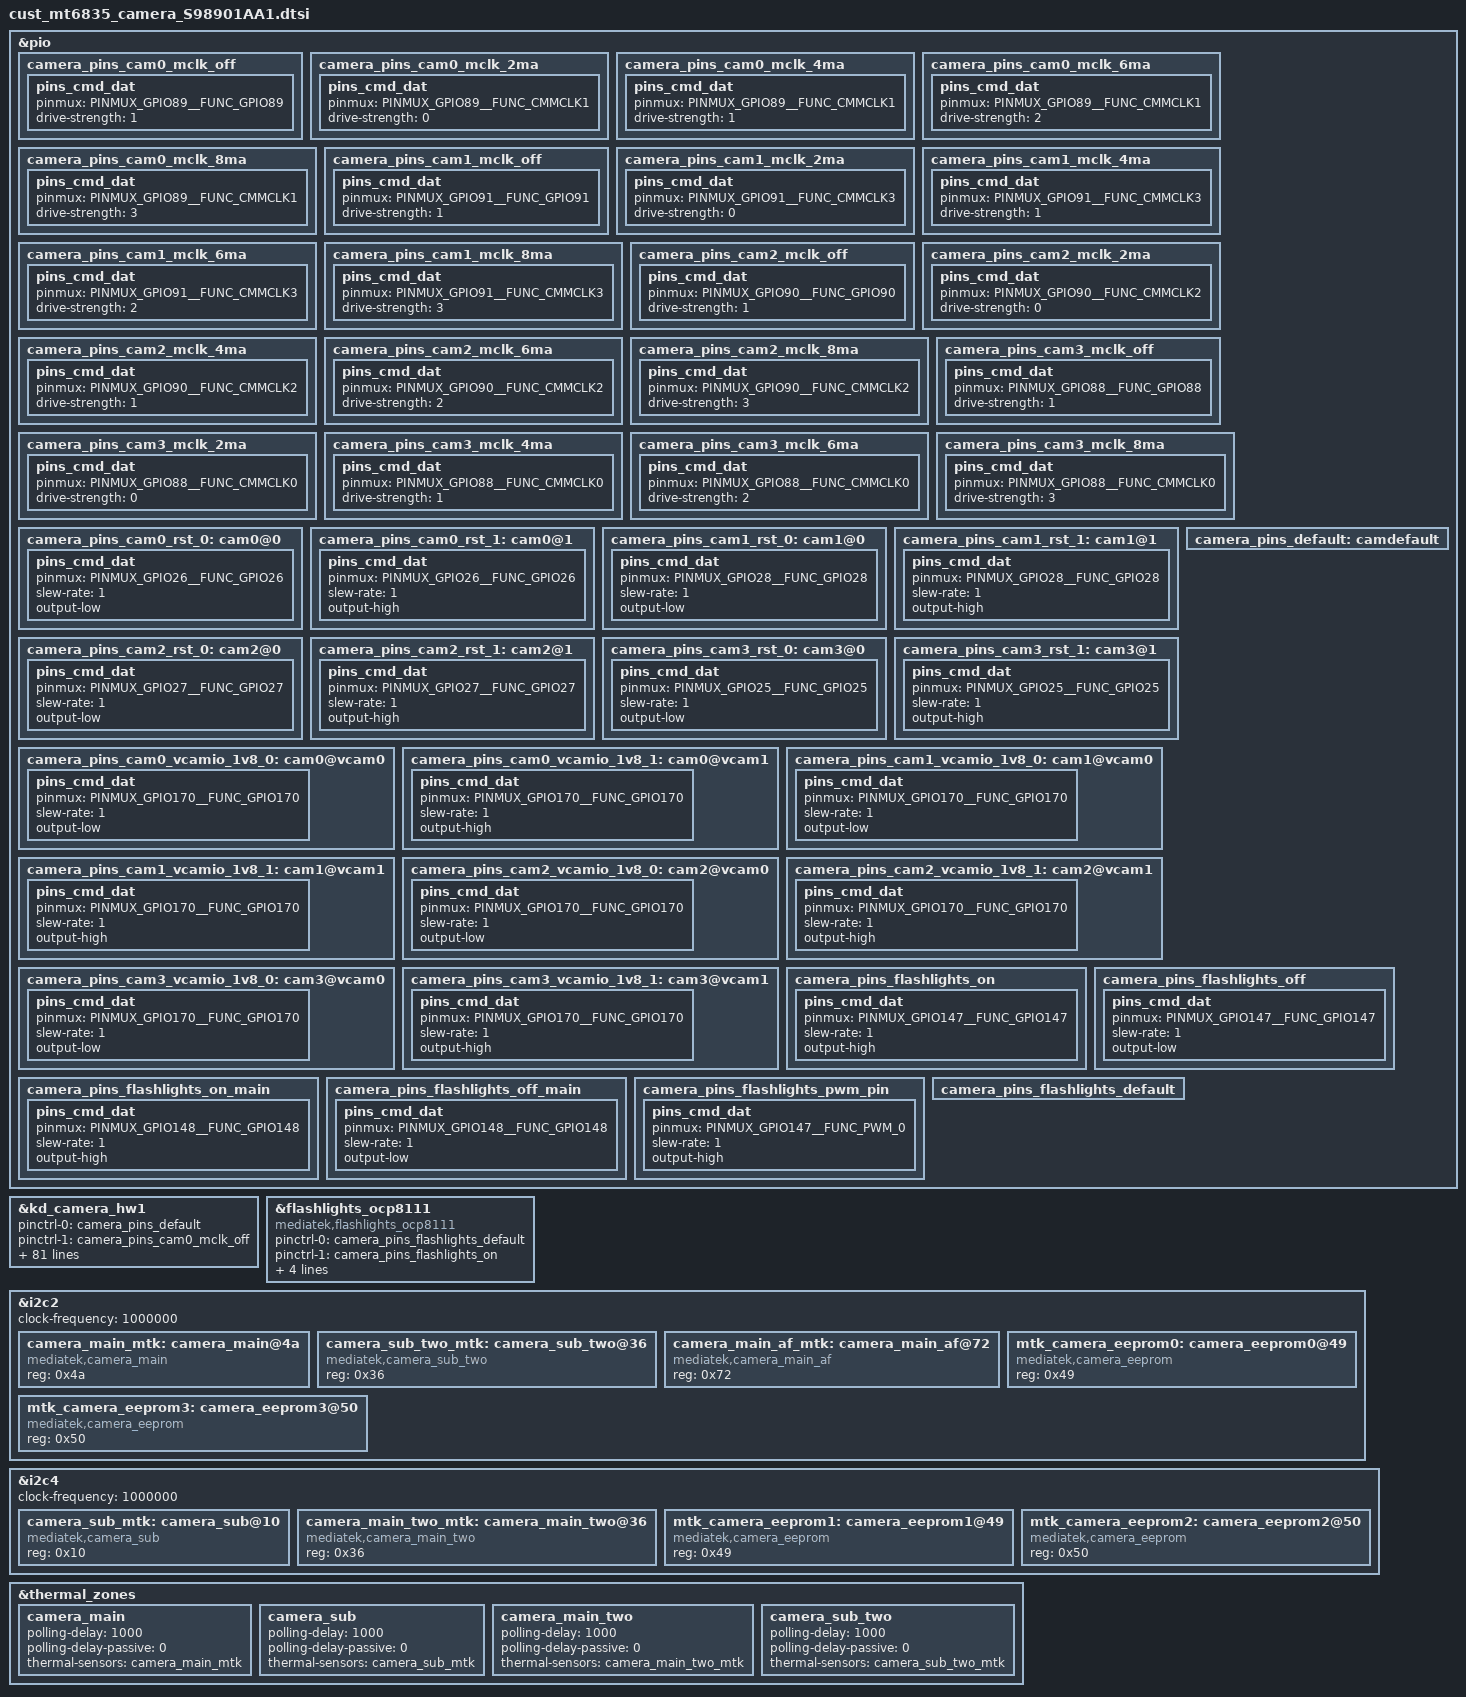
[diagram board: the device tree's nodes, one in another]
// SPDX-License-Identifier: GPL-2.0
/* Copyright (c) 2020 MediaTek Inc. */
#include "mediatek/et5904.dtsi"

/* CAMERA GPIO standardization */
&pio {
	camera_pins_cam0_mclk_off: camera_pins_cam0_mclk_off {
		pins_cmd_dat {
			pinmux = <PINMUX_GPIO89__FUNC_GPIO89>;
			drive-strength = <1>;
		};
	};
	camera_pins_cam0_mclk_2ma: camera_pins_cam0_mclk_2ma {
		pins_cmd_dat {
			pinmux = <PINMUX_GPIO89__FUNC_CMMCLK1>;
			drive-strength = <0>;
		};
	};
	camera_pins_cam0_mclk_4ma: camera_pins_cam0_mclk_4ma {
		pins_cmd_dat {
			pinmux = <PINMUX_GPIO89__FUNC_CMMCLK1>;
			drive-strength = <1>;
		};
	};
	camera_pins_cam0_mclk_6ma: camera_pins_cam0_mclk_6ma {
		pins_cmd_dat {
			pinmux = <PINMUX_GPIO89__FUNC_CMMCLK1>;
			drive-strength = <2>;
		};
	};
	camera_pins_cam0_mclk_8ma: camera_pins_cam0_mclk_8ma {
		pins_cmd_dat {
			pinmux = <PINMUX_GPIO89__FUNC_CMMCLK1>;
			drive-strength = <3>;
		};
	};

	camera_pins_cam1_mclk_off: camera_pins_cam1_mclk_off {
		pins_cmd_dat {
			pinmux = <PINMUX_GPIO91__FUNC_GPIO91>;
			drive-strength = <1>;
		};
	};
	camera_pins_cam1_mclk_2ma: camera_pins_cam1_mclk_2ma {
		pins_cmd_dat {
			pinmux = <PINMUX_GPIO91__FUNC_CMMCLK3>;
			drive-strength = <0>;
		};
	};
	camera_pins_cam1_mclk_4ma: camera_pins_cam1_mclk_4ma {
		pins_cmd_dat {
			pinmux = <PINMUX_GPIO91__FUNC_CMMCLK3>;
			drive-strength = <1>;
		};
	};
	camera_pins_cam1_mclk_6ma: camera_pins_cam1_mclk_6ma {
		pins_cmd_dat {
			pinmux = <PINMUX_GPIO91__FUNC_CMMCLK3>;
			drive-strength = <2>;
		};
	};
	camera_pins_cam1_mclk_8ma: camera_pins_cam1_mclk_8ma {
		pins_cmd_dat {
			pinmux = <PINMUX_GPIO91__FUNC_CMMCLK3>;
			drive-strength = <3>;
		};
	};
	camera_pins_cam2_mclk_off: camera_pins_cam2_mclk_off {
		pins_cmd_dat {
			pinmux = <PINMUX_GPIO90__FUNC_GPIO90>;
			drive-strength = <1>;
		};
	};
	camera_pins_cam2_mclk_2ma: camera_pins_cam2_mclk_2ma {
		pins_cmd_dat {
			pinmux = <PINMUX_GPIO90__FUNC_CMMCLK2>;
			drive-strength = <0>;
		};
	};
	camera_pins_cam2_mclk_4ma: camera_pins_cam2_mclk_4ma {
		pins_cmd_dat {
			pinmux = <PINMUX_GPIO90__FUNC_CMMCLK2>;
			drive-strength = <1>;
		};
	};
	camera_pins_cam2_mclk_6ma: camera_pins_cam2_mclk_6ma {
		pins_cmd_dat {
			pinmux = <PINMUX_GPIO90__FUNC_CMMCLK2>;
			drive-strength = <2>;
		};
	};
	camera_pins_cam2_mclk_8ma: camera_pins_cam2_mclk_8ma {
		pins_cmd_dat {
			pinmux = <PINMUX_GPIO90__FUNC_CMMCLK2>;
			drive-strength = <3>;
		};
	};

	camera_pins_cam3_mclk_off: camera_pins_cam3_mclk_off {
		pins_cmd_dat {
			pinmux = <PINMUX_GPIO88__FUNC_GPIO88>;
			drive-strength = <1>;
		};
	};
	camera_pins_cam3_mclk_2ma: camera_pins_cam3_mclk_2ma {
		pins_cmd_dat {
			pinmux = <PINMUX_GPIO88__FUNC_CMMCLK0>;
			drive-strength = <0>;
		};
	};
	camera_pins_cam3_mclk_4ma: camera_pins_cam3_mclk_4ma {
		pins_cmd_dat {
			pinmux = <PINMUX_GPIO88__FUNC_CMMCLK0>;
			drive-strength = <1>;
		};
	};
	camera_pins_cam3_mclk_6ma: camera_pins_cam3_mclk_6ma {
		pins_cmd_dat {
			pinmux = <PINMUX_GPIO88__FUNC_CMMCLK0>;
			drive-strength = <2>;
		};
	};
	camera_pins_cam3_mclk_8ma: camera_pins_cam3_mclk_8ma {
		pins_cmd_dat {
			pinmux = <PINMUX_GPIO88__FUNC_CMMCLK0>;
			drive-strength = <3>;
		};
	};


	camera_pins_cam0_rst_0: cam0@0 {
		pins_cmd_dat {
			pinmux = <PINMUX_GPIO26__FUNC_GPIO26>;
			slew-rate = <1>;
			output-low;
		};
	};
	camera_pins_cam0_rst_1: cam0@1 {
		pins_cmd_dat {
			pinmux = <PINMUX_GPIO26__FUNC_GPIO26>;
			slew-rate = <1>;
			output-high;
		};
	};

	camera_pins_cam1_rst_0: cam1@0 {
		pins_cmd_dat {
			pinmux = <PINMUX_GPIO28__FUNC_GPIO28>;
			slew-rate = <1>;
			output-low;
		};
	};
	camera_pins_cam1_rst_1: cam1@1 {
		pins_cmd_dat {
			pinmux = <PINMUX_GPIO28__FUNC_GPIO28>;
			slew-rate = <1>;
			output-high;
		};
	};
	camera_pins_cam2_rst_0: cam2@0 {
		pins_cmd_dat {
			pinmux = <PINMUX_GPIO27__FUNC_GPIO27>;
			slew-rate = <1>;
			output-low;
		};
	};
	camera_pins_cam2_rst_1: cam2@1 {
		pins_cmd_dat {
			pinmux = <PINMUX_GPIO27__FUNC_GPIO27>;
			slew-rate = <1>;
			output-high;
		};
	};
		camera_pins_cam3_rst_0: cam3@0 {
		pins_cmd_dat {
			pinmux = <PINMUX_GPIO25__FUNC_GPIO25>;
			slew-rate = <1>;
			output-low;
		};
	};
	camera_pins_cam3_rst_1: cam3@1 {
		pins_cmd_dat {
			pinmux = <PINMUX_GPIO25__FUNC_GPIO25>;
			slew-rate = <1>;
			output-high;
		};
	};

	camera_pins_cam0_vcamio_1v8_0: cam0@vcam0 {
		pins_cmd_dat {
			pinmux = <PINMUX_GPIO170__FUNC_GPIO170>;
			slew-rate = <1>;
			output-low;
		};
	};
	camera_pins_cam0_vcamio_1v8_1: cam0@vcam1 {
		pins_cmd_dat {
			pinmux = <PINMUX_GPIO170__FUNC_GPIO170>;
			slew-rate = <1>;
			output-high;
		};
	};
	camera_pins_cam1_vcamio_1v8_0: cam1@vcam0 {
		pins_cmd_dat {
			pinmux = <PINMUX_GPIO170__FUNC_GPIO170>;
			slew-rate = <1>;
			output-low;
		};
	};
	camera_pins_cam1_vcamio_1v8_1: cam1@vcam1 {
		pins_cmd_dat {
			pinmux = <PINMUX_GPIO170__FUNC_GPIO170>;
			slew-rate = <1>;
			output-high;
		};
	};
	camera_pins_cam2_vcamio_1v8_0: cam2@vcam0 {
		pins_cmd_dat {
			pinmux = <PINMUX_GPIO170__FUNC_GPIO170>;
			slew-rate = <1>;
			output-low;
		};
	};
	camera_pins_cam2_vcamio_1v8_1: cam2@vcam1 {
		pins_cmd_dat {
			pinmux = <PINMUX_GPIO170__FUNC_GPIO170>;
			slew-rate = <1>;
			output-high;
		};
	};
	camera_pins_cam3_vcamio_1v8_0: cam3@vcam0 {
		pins_cmd_dat {
			pinmux = <PINMUX_GPIO170__FUNC_GPIO170>;
			slew-rate = <1>;
			output-low;
		};
	};
	camera_pins_cam3_vcamio_1v8_1: cam3@vcam1 {
		pins_cmd_dat {
			pinmux = <PINMUX_GPIO170__FUNC_GPIO170>;
			slew-rate = <1>;
			output-high;
		};
	};

	camera_pins_default: camdefault {
	};
};

&kd_camera_hw1 {
	pinctrl-names = "default",
			"cam0_mclk_off",
			"cam0_mclk_2mA", "cam0_mclk_4mA",
			"cam0_mclk_6mA", "cam0_mclk_8mA",
			"cam1_mclk_off",
			"cam1_mclk_2mA", "cam1_mclk_4mA",
			"cam1_mclk_6mA", "cam1_mclk_8mA",
			"cam2_mclk_off",
			"cam2_mclk_2mA", "cam2_mclk_4mA",
			"cam2_mclk_6mA", "cam2_mclk_8mA",
			"cam3_mclk_off",
			"cam3_mclk_2mA", "cam3_mclk_4mA",
			"cam3_mclk_6mA", "cam3_mclk_8mA",
			"cam0_rst0", "cam0_rst1",
			"cam1_rst0", "cam1_rst1",
			"cam2_rst0", "cam2_rst1",
			"cam3_rst0", "cam3_rst1",
			"cam0_ldo_vcamio_0", "cam0_ldo_vcamio_1",
			"cam1_ldo_vcamio_0", "cam1_ldo_vcamio_1",
			"cam2_ldo_vcamio_0", "cam2_ldo_vcamio_1",
			"cam3_ldo_vcamio_0", "cam3_ldo_vcamio_1";

    pinctrl-0 = <&camera_pins_default>;
	pinctrl-1 = <&camera_pins_cam0_mclk_off>;
	pinctrl-2 = <&camera_pins_cam0_mclk_2ma>;
	pinctrl-3 = <&camera_pins_cam0_mclk_4ma>;
	pinctrl-4 = <&camera_pins_cam0_mclk_6ma>;
	pinctrl-5 = <&camera_pins_cam0_mclk_8ma>;
	pinctrl-6 = <&camera_pins_cam1_mclk_off>;
	pinctrl-7 = <&camera_pins_cam1_mclk_2ma>;
	pinctrl-8 = <&camera_pins_cam1_mclk_4ma>;
	pinctrl-9 = <&camera_pins_cam1_mclk_6ma>;
	pinctrl-10 = <&camera_pins_cam1_mclk_8ma>;
	pinctrl-11 = <&camera_pins_cam2_mclk_off>;
	pinctrl-12 = <&camera_pins_cam2_mclk_2ma>;
	pinctrl-13 = <&camera_pins_cam2_mclk_4ma>;
	pinctrl-14 = <&camera_pins_cam2_mclk_6ma>;
	pinctrl-15 = <&camera_pins_cam2_mclk_8ma>;
	pinctrl-16 = <&camera_pins_cam3_mclk_off>;
	pinctrl-17 = <&camera_pins_cam3_mclk_2ma>;
	pinctrl-18 = <&camera_pins_cam3_mclk_4ma>;
	pinctrl-19 = <&camera_pins_cam3_mclk_6ma>;
	pinctrl-20 = <&camera_pins_cam3_mclk_8ma>;
	pinctrl-21 = <&camera_pins_cam0_rst_0>;
	pinctrl-22 = <&camera_pins_cam0_rst_1>;
	pinctrl-23 = <&camera_pins_cam1_rst_0>;
	pinctrl-24 = <&camera_pins_cam1_rst_1>;
	pinctrl-25 = <&camera_pins_cam2_rst_0>;
	pinctrl-26 = <&camera_pins_cam2_rst_1>;
	pinctrl-27 = <&camera_pins_cam3_rst_0>;
	pinctrl-28 = <&camera_pins_cam3_rst_1>;
	pinctrl-29 = <&camera_pins_cam0_vcamio_1v8_0>;
	pinctrl-30 = <&camera_pins_cam0_vcamio_1v8_1>;
	pinctrl-31 = <&camera_pins_cam1_vcamio_1v8_0>;
	pinctrl-32 = <&camera_pins_cam1_vcamio_1v8_1>;
	pinctrl-33 = <&camera_pins_cam2_vcamio_1v8_0>;
	pinctrl-34 = <&camera_pins_cam2_vcamio_1v8_1>;
	pinctrl-35 = <&camera_pins_cam3_vcamio_1v8_0>;
	pinctrl-36 = <&camera_pins_cam3_vcamio_1v8_1>;

	cam0_vcama-supply = <&et04_ldo3>;
	cam1_vcama-supply = <&et04_ldo3>;
	cam2_vcama-supply = <&et04_ldo3>;
	cam3_vcama-supply = <&et04_ldo3>;
	cam0_vcamd-supply = <&et04_ldo2>;
	cam1_vcamd-supply = <&et04_ldo2>;
	cam2_vcamd-supply = <&et04_ldo1>;
	cam0_vcamaf-supply = <&et04_ldo4>;

	cam0_vcama1-supply = <&et04_ldo1>; //wide DVDD
	cam1_vcama1-supply = <&et04_ldo1>; //wide DVDD
	cam2_vcama1-supply = <&et04_ldo2>; //front main/front DVDD
	cam3_vcama1-supply = <&et04_ldo2>; //front main/front DVDD
	cam3_vcamd-supply  = <&et04_ldo1>; //wide DVDD

	cam0_enable_sensor = "w3s5kjn1reartxd_mipi_raw w3hi5022qrearjk_mipi_raw w3gc50e0reartxd_mipi_raw";
	cam1_enable_sensor = "w3ov13b10frontdc_mipi_raw w3gc13a0frontlh_mipi_raw w3sc1321csfrontlce_mipi_raw w3sc1300csfronttxd_mipi_raw";
	cam2_enable_sensor = "w3gc5035widesj_mipi_raw w3sc520cswidelce_mipi_raw";
	cam3_enable_sensor = "w3sc201acsmicrocxt_mipi_raw w3gc02m3microlh_mipi_raw w3c2599microsj_mipi_raw";

	cam0_pin_mclk = "mclk";
	cam0_pin_rst = "gpio";
	cam0_pin_vcama = "regulator";
	cam0_pin_vcamio = "gpio";
	cam0_pin_vcamd = "regulator";
	cam0_pin_vcamaf = "regulator";
	cam1_pin_mclk = "mclk";
	cam1_pin_rst = "gpio";
	cam1_pin_vcama = "regulator";
	cam1_pin_vcamio = "gpio";
	cam1_pin_vcamd = "regulator";
	cam2_pin_mclk = "mclk";
	cam2_pin_rst = "gpio";
	cam2_pin_vcama = "regulator";
	cam2_pin_vcamio = "gpio";
	cam2_pin_vcamd = "regulator";
	cam3_pin_mclk = "mclk";
	cam3_pin_rst = "gpio";
	cam3_pin_vcama = "regulator";
	cam3_pin_vcamio = "gpio";

	cam0_pin_vcama1 = "regulator";
	cam1_pin_vcama1 = "regulator";
	cam2_pin_vcama1 = "regulator";
	cam3_pin_vcama1 = "regulator";
	cam3_pin_vcamd  = "regulator";

	status = "okay";
};


&pio {
	camera_pins_flashlights_on: camera_pins_flashlights_on {
		pins_cmd_dat {
			pinmux = <PINMUX_GPIO147__FUNC_GPIO147>;
			slew-rate = <1>;
			output-high;
		};
	};
	camera_pins_flashlights_off: camera_pins_flashlights_off {
		pins_cmd_dat {
			pinmux = <PINMUX_GPIO147__FUNC_GPIO147>;
			slew-rate = <1>;
			output-low;
		};
	};
	camera_pins_flashlights_on_main: camera_pins_flashlights_on_main {
		pins_cmd_dat {
			pinmux = <PINMUX_GPIO148__FUNC_GPIO148>;
			slew-rate = <1>;
			output-high;
		};
	};
	camera_pins_flashlights_off_main: camera_pins_flashlights_off_main {
		pins_cmd_dat {
			pinmux = <PINMUX_GPIO148__FUNC_GPIO148>;
			slew-rate = <1>;
			output-low;
		};
	};
	camera_pins_flashlights_pwm_pin: camera_pins_flashlights_pwm_pin {
		pins_cmd_dat {
			pinmux = <PINMUX_GPIO147__FUNC_PWM_0>;
			slew-rate = <1>;
			output-high;
		};
	};


	camera_pins_flashlights_default: camera_pins_flashlights_default {
	};
};

&flashlights_ocp8111 {
		compatible = "mediatek,flashlights_ocp8111";
		pinctrl-names = "default",
			"flashlights_on",
			"flashlights_off",
			"flashlights_on_main",
			"flashlights_off_main",
			"flashlights_pwm_pin";

		pinctrl-0 = <&camera_pins_flashlights_default>;
		pinctrl-1 = <&camera_pins_flashlights_on>;
		pinctrl-2 = <&camera_pins_flashlights_off>;
		pinctrl-3 = <&camera_pins_flashlights_on_main>;
		pinctrl-4 = <&camera_pins_flashlights_off_main>;
		pinctrl-5 = <&camera_pins_flashlights_pwm_pin>;
};

/* CAMERA GPIO end */

&i2c2 {
	status = "okay";
	clock-frequency = <1000000>;
	#address-cells = <1>;
	#size-cells = <0>;

	camera_main_mtk:camera_main@4a {
		compatible = "mediatek,camera_main";
		#thermal-sensor-cells = <0>;
		reg = <0x4a>;
		status = "okay";
	};
	camera_sub_two_mtk:camera_sub_two@36 {
		compatible = "mediatek,camera_sub_two";
		#thermal-sensor-cells = <0>;
		reg = <0x36>;
		status = "okay";
	};
	camera_main_af_mtk:camera_main_af@72 {
		compatible = "mediatek,camera_main_af";
		reg = <0x72>;
		status = "okay";
	};
	mtk_camera_eeprom0:camera_eeprom0@49 {
		compatible = "mediatek,camera_eeprom";
		reg = <0x49>;
		status = "okay";
	};
	mtk_camera_eeprom3:camera_eeprom3@50 {
		compatible = "mediatek,camera_eeprom";
		reg = <0x50>;
		status = "okay";
	};
};


&i2c4 {
	status = "okay";
	clock-frequency = <1000000>;
	#address-cells = <1>;
	#size-cells = <0>;

	camera_sub_mtk:camera_sub@10 {
		compatible = "mediatek,camera_sub";
		#thermal-sensor-cells = <0>;
		reg = <0x10>;
		status = "okay";
	};
	camera_main_two_mtk:camera_main_two@36 {
		compatible = "mediatek,camera_main_two";
		#thermal-sensor-cells = <0>;
		reg = <0x36>;
		status = "okay";
	};
	mtk_camera_eeprom1:camera_eeprom1@49 {
		compatible = "mediatek,camera_eeprom";
		reg = <0x49>;
		status = "okay";
	};
	mtk_camera_eeprom2:camera_eeprom2@50 {
		compatible = "mediatek,camera_eeprom";
		reg = <0x50>;
		status = "okay";
	};
};

/* CAMERA TZ config */
&thermal_zones {
	camera_main: camera_main {
		polling-delay = <1000>; /* milliseconds */
		polling-delay-passive = <0>; /* milliseconds */
		thermal-sensors = <&camera_main_mtk>;
	};
	camera_sub: camera_sub {
		polling-delay = <1000>; /* milliseconds */
		polling-delay-passive = <0>; /* milliseconds */
		thermal-sensors = <&camera_sub_mtk>;
	};
	camera_main_two: camera_main_two {
		polling-delay = <1000>; /* milliseconds */
		polling-delay-passive = <0>; /* milliseconds */
		thermal-sensors = <&camera_main_two_mtk>;
	};
	camera_sub_two: camera_sub_two {
		polling-delay = <1000>; /* milliseconds */
		polling-delay-passive = <0>; /* milliseconds */
		thermal-sensors = <&camera_sub_two_mtk>;
	};
};
/* CAMERA TZ config end */
